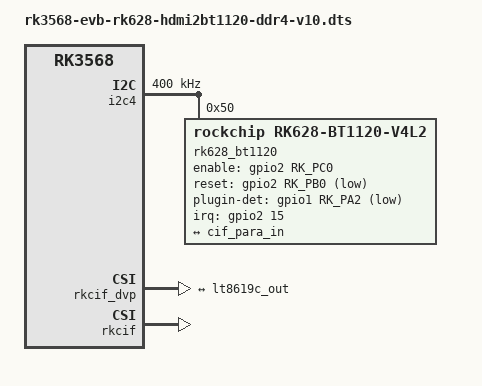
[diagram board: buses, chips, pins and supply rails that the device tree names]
// SPDX-License-Identifier: (GPL-2.0+ OR MIT)
/*
 * Copyright (c) 2023 Rockchip Electronics Co., Ltd.
 *
 */

#include "rk3568-evb-rk628-ddr4-v10.dtsi"
#include "rk3568-android.dtsi"

&i2c4 {
	pinctrl-names = "default";
	pinctrl-0 = <&i2c4m1_xfer>;
	clock-frequency = <400000>;
	status = "okay";

	rk628_bt1120: rk628_bt1120@50 {
		compatible = "rockchip,rk628-bt1120-v4l2";
		reg = <0x50>;
		status = "okay";
		pinctrl-names = "default";
		pinctrl-0 = <&cif_dvp_clk &cif_dvp_bus16 &cif_dvp_bus8>;
		interrupt-parent = <&gpio2>;
		interrupts = <15 IRQ_TYPE_LEVEL_HIGH>;
		enable-gpios = <&gpio2 RK_PC0 GPIO_ACTIVE_HIGH>;
		reset-gpios = <&gpio2 RK_PB0 GPIO_ACTIVE_LOW>;
		plugin-det-gpios = <&gpio1 RK_PA2 GPIO_ACTIVE_LOW>;
		rockchip,camera-module-index = <0>;
		rockchip,camera-module-facing = "back";
		rockchip,camera-module-name = "RK628-BT1120";
		rockchip,camera-module-lens-name = "NC";
		dual-edge = <1>;

		port {
			lt8619c_out: endpoint {
				remote-endpoint = <&cif_para_in>;
				bus-width = <16>;
				pclk-sample = <1>;
			};
		};
	};
};

&rkcif_dvp {
	status = "okay";

	port {
		/* Parallel bus endpoint */
		cif_para_in: endpoint {
			remote-endpoint = <&lt8619c_out>;
		};
	};
};

&rkcif {
	status = "okay";
};

&rkcif_mmu {
	status = "okay";
};
